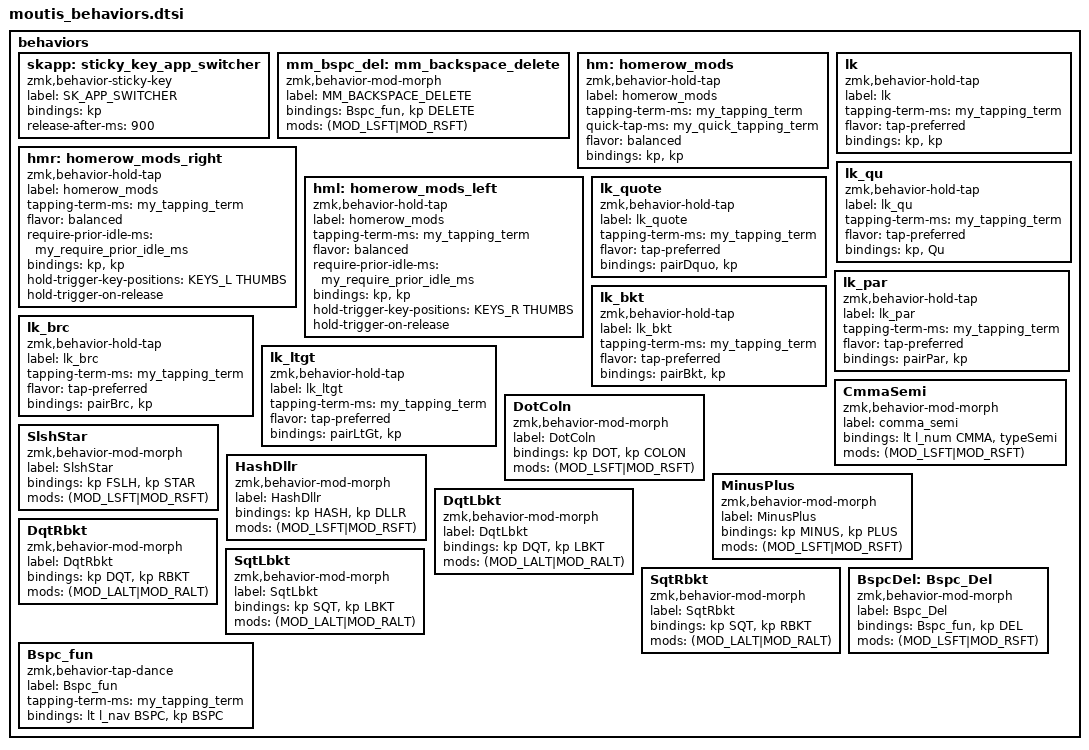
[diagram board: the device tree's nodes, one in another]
/*       KEY POSITIONS for Corne-ish Zen
    ╭─────────────────────╮ ╭─────────────────────╮
  0 │   1   2   3   4  5  │ │  6   7   8   9  10  │ 11
 12 │  13  14  15  16  17 | | 18  19  20  21  22  │ 23
 24 │  25  26  27  28  29 │ │ 30  31  32  33  34  │ 35
    ╰────────╮ 36  37  38 │ │ 39  40  41 ╭────────╯
             ╰────────────╯ ╰────────────╯
*/
/*    KEY POSITION Names
    ╭─────────────────────╮ ╭─────────────────────╮
LT5 │ LT4 LT3 LT2 LT1 LT0 │ │ RT0 RT1 RT2 RT3 RT4 │ RT5
LM5 │ LM4 LM3 LM2 LM1 LM0 │ │ RM0 RM1 RM2 RM3 RM4 │ RM5
LB5 │ LB4 LB3 LB2 LB1 LB0 │ │ RB0 RB1 RB2 RB3 RB4 │ RB5
    ╰───────╮ LH3 LH2 LH1 | | RH1 RH2 RH3 ╭───────╯
            ╰─────────────╯ ╰─────────────╯
*/
/*  Base (alpha) Layer  Hands Down Vibranium-vv
    Building for a 36/42 key board
    ╭─────────────────────╮ ╭──────────────────────╮
LT5 │  X   W   M   G  "[  │ │  #$  .:  ']   J   B  │ RT5
LM5 │  S   C   N   T   K  | |  ,;   A   E   I   H  │ RM5
LB5 │  V   P   L   D   /* │ │  -+   U   O   Y   F  │ RB5
    ╰──────╮  App BSP  R  │ │  SPC RET  TAB ╭──────╯
           ╰──────────────╯ ╰───────────────╯
*/

behaviors {
      skapp: sticky_key_app_switcher {
        compatible = "zmk,behavior-sticky-key";
        label = "SK_APP_SWITCHER";
        #binding-cells = <1>;
        bindings = <&kp>;
        release-after-ms = <900>;
      };
        mm_bspc_del: mm_backspace_delete {
            compatible = "zmk,behavior-mod-morph";
            label = "MM_BACKSPACE_DELETE";
            #binding-cells = <0>;
            bindings = <&Bspc_fun>, <&kp DELETE>;
            mods = <(MOD_LSFT|MOD_RSFT)>;
        };
        hm: homerow_mods { // use on either hand
            compatible = "zmk,behavior-hold-tap";
            label = "homerow_mods";
            #binding-cells = <2>;
            tapping-term-ms = <my_tapping_term>;
            quick-tap-ms = <my_quick_tapping_term>;
            flavor = "balanced";
            bindings = <&kp>, <&kp>;
        };
        hmr: homerow_mods_right { // use on right hand to mod left
            compatible = "zmk,behavior-hold-tap";
            label = "homerow_mods";
            #binding-cells = <2>;
            tapping-term-ms = <my_tapping_term>;
            flavor = "balanced";
            require-prior-idle-ms = <my_require_prior_idle_ms>;
            bindings = <&kp>, <&kp>;
            hold-trigger-key-positions = <KEYS_L THUMBS>; // left hand allowed
            hold-trigger-on-release;
        };
        hml: homerow_mods_left { // use on left hand to mod right
            compatible = "zmk,behavior-hold-tap";
            label = "homerow_mods";
            #binding-cells = <2>;
            tapping-term-ms = <my_tapping_term>;
            flavor = "balanced";
            require-prior-idle-ms = <my_require_prior_idle_ms>;
            bindings = <&kp>, <&kp>;
            hold-trigger-key-positions = <KEYS_R THUMBS>; // right hand allowed
            hold-trigger-on-release;
        };
        lk: lk {
            compatible = "zmk,behavior-hold-tap";
            label = "lk";
            #binding-cells = <2>;
            tapping-term-ms = <my_tapping_term>;
            flavor = "tap-preferred";
            bindings = <&kp>, <&kp>;
        };
        lk_qu: lk_qu {
            compatible = "zmk,behavior-hold-tap";
            label = "lk_qu";
            #binding-cells = <2>;
            tapping-term-ms = <my_tapping_term>;
            flavor = "tap-preferred";
            bindings = <&kp>, <&Qu>;
        };
        lk_quote: lk_quote { // " on tap, “” on "linger" (curly quotes)
            compatible = "zmk,behavior-hold-tap";
            label = "lk_quote";
            #binding-cells = <2>;
            tapping-term-ms = <my_tapping_term>;
            flavor = "tap-preferred";
            bindings = <&pairDquo>, <&kp>;
        };
        lk_par: lk_par { // ( on tap, () on "linger"
            compatible = "zmk,behavior-hold-tap";
            label = "lk_par";
            #binding-cells = <2>;
            tapping-term-ms = <my_tapping_term>;
            flavor = "tap-preferred";
            bindings = <&pairPar>, <&kp>;
        };
        lk_bkt: lk_bkt { // [ on tap, [] on "linger"
            compatible = "zmk,behavior-hold-tap";
            label = "lk_bkt";
            #binding-cells = <2>;
            tapping-term-ms = <my_tapping_term>;
            flavor = "tap-preferred";
            bindings = <&pairBkt>, <&kp>;
        };
        lk_brc: lk_brc { // { on tap, {} on "linger"
            compatible = "zmk,behavior-hold-tap";
            label = "lk_brc";
            #binding-cells = <2>;
            tapping-term-ms = <my_tapping_term>;
            flavor = "tap-preferred";
            bindings = <&pairBrc>, <&kp>;
        };
        lk_ltgt: lk_ltgt { // < on tap, <|> on "linger"
            compatible = "zmk,behavior-hold-tap";
            label = "lk_ltgt";
            #binding-cells = <2>;
            tapping-term-ms = <my_tapping_term>;
            flavor = "tap-preferred";
            bindings = <&pairLtGt>, <&kp>;
        };

        CmmaSemi: CmmaSemi {
            compatible = "zmk,behavior-mod-morph";
            label = "comma_semi";
            #binding-cells = <0>;
            bindings = <&lt l_num CMMA>, <&typeSemi>;
            mods = <(MOD_LSFT|MOD_RSFT)>;
        };
        DotColn: DotColn {
            compatible = "zmk,behavior-mod-morph";
            label = "DotColn";
            #binding-cells = <0>;
            bindings = <&kp DOT>, <&kp COLON>;
            mods = <(MOD_LSFT|MOD_RSFT)>;
        };
        SlshStar: SlshStar {
            compatible = "zmk,behavior-mod-morph";
            label = "SlshStar";
            #binding-cells = <0>;
            bindings = <&kp FSLH>, <&kp STAR>;
            mods = <(MOD_LSFT|MOD_RSFT)>;
        };
        HashDllr: HashDllr {
            compatible = "zmk,behavior-mod-morph";
            label = "HashDllr";
            #binding-cells = <0>;
            bindings = <&kp HASH>, <&kp DLLR>;
            mods = <(MOD_LSFT|MOD_RSFT)>;
        };
        MinusPlus: MinusPlus {
            compatible = "zmk,behavior-mod-morph";
            label = "MinusPlus";
            #binding-cells = <0>;
            bindings = <&kp MINUS>, <&kp PLUS>;
            mods = <(MOD_LSFT|MOD_RSFT)>;
        };
        DqtLbkt: DqtLbkt {
            compatible = "zmk,behavior-mod-morph";
            label = "DqtLbkt";
            #binding-cells = <0>;
            bindings = <&kp DQT>, <&kp LBKT>;
            mods = <(MOD_LALT|MOD_RALT)>;
        };
        DqtRbkt: DqtRbkt {
            compatible = "zmk,behavior-mod-morph";
            label = "DqtRbkt";
            #binding-cells = <0>;
            bindings = <&kp DQT>, <&kp RBKT>;
            mods = <(MOD_LALT|MOD_RALT)>;
        };
        SqtLbkt: SqtLbkt {
            compatible = "zmk,behavior-mod-morph";
            label = "SqtLbkt";
            #binding-cells = <0>;
            bindings = <&kp SQT>, <&kp LBKT>;
            mods = <(MOD_LALT|MOD_RALT)>;
        };
        SqtRbkt: SqtRbkt {
            compatible = "zmk,behavior-mod-morph";
            label = "SqtRbkt";
            #binding-cells = <0>;
            bindings = <&kp SQT>, <&kp RBKT>;
            mods = <(MOD_LALT|MOD_RALT)>;
        };
        BspcDel: Bspc_Del {
            compatible = "zmk,behavior-mod-morph";
            label = "Bspc_Del";
            #binding-cells = <0>;
            bindings = <&Bspc_fun>, <&kp DEL>;
            mods = <(MOD_LSFT|MOD_RSFT)>;
        };
        Bspc_fun: Bspc_fun {
            compatible = "zmk,behavior-tap-dance";
            label = "Bspc_fun";
            #binding-cells = <0>;
            tapping-term-ms = <my_tapping_term>;
            bindings = <&lt l_nav BSPC>, <&kp BSPC>;
        };
};
